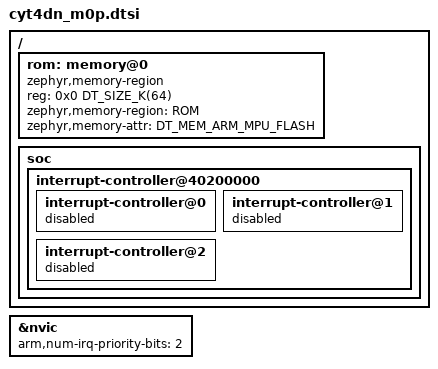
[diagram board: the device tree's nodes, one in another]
/*
 * SPDX-FileCopyrightText: Copyright (c) 2026 Linumiz
 *
 * SPDX-License-Identifier: Apache-2.0
 */

#include <mem.h>
#include <arm/armv6-m.dtsi>
#include <zephyr/dt-bindings/memory-attr/memory-attr-arm.h>

/ {
	rom: memory@0 {
		compatible = "zephyr,memory-region";
		reg = <0x0 DT_SIZE_K(64)>;
		zephyr,memory-region = "ROM";
		zephyr,memory-attr = <DT_MEM_ARM_MPU_FLASH>;
	};
};

&nvic {
	arm,num-irq-priority-bits = <2>;
};

/ {
	soc {
		interrupt-controller@40200000 {
			/* NvicMux0-2 are reserved for the SROM handlers and the trampoline */
			interrupt-controller@0 {
				status = "disabled";
			};

			interrupt-controller@1 {
				status = "disabled";
			};

			interrupt-controller@2 {
				status = "disabled";
			};
		};
	};
};
